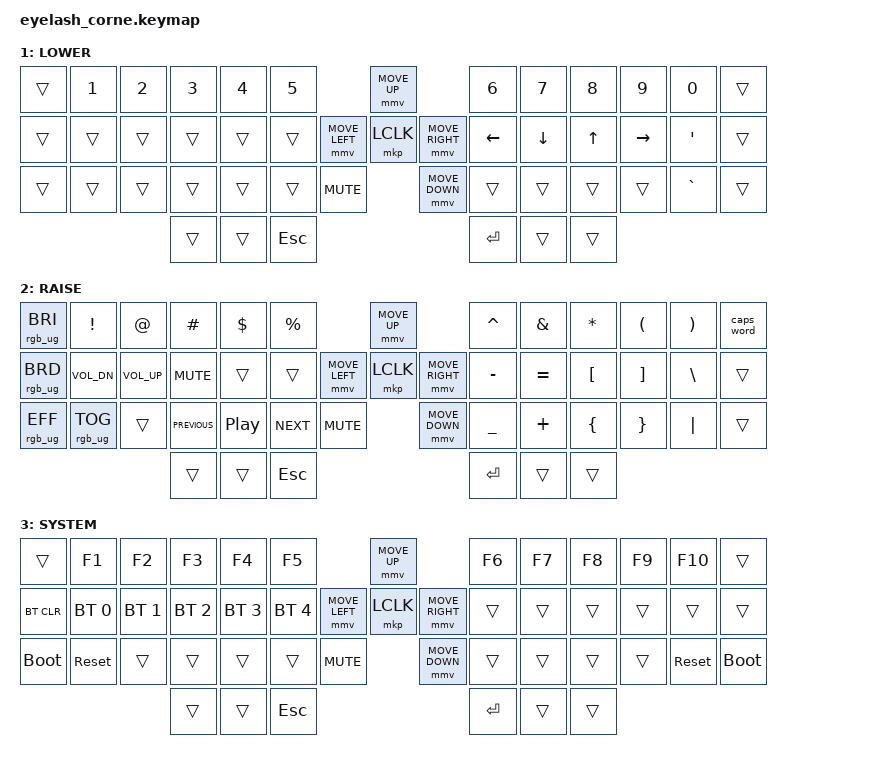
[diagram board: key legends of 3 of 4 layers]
#define ZMK_POINTING_DEFAULT_MOVE_VAL 1200  // 600
#define ZMK_POINTING_DEFAULT_SCRL_VAL 25   // 10

#include <input/processors.dtsi>
#include <zephyr/dt-bindings/input/input-event-codes.h>
#include <behaviors.dtsi>
#include <dt-bindings/zmk/bt.h>
#include <dt-bindings/zmk/keys.h>
#include <dt-bindings/zmk/outputs.h>
#include <dt-bindings/zmk/pointing.h>
#include <dt-bindings/zmk/rgb.h>

#define HRML(k1,k2,k3,k4) &ht LSHFT k1  &ht LALT k2  &ht LCTRL k3  &ht LGUI k4
#define HRMR(k1,k2,k3,k4) &ht RGUI k1  &ht RCTRL k2  &ht RALT k3  &ht RSHFT k4

&mmv_input_listener { input-processors = <&zip_xy_scaler 2 1>; };

&msc_input_listener { input-processors = <&zip_scroll_scaler 2 1>; };

&msc {
    acceleration-exponent = <1>;      // 0
    time-to-max-speed-ms = <100>;       // 300
    delay-ms = <0>;                   // 0
};

&mmv {
    time-to-max-speed-ms = <500>;
    acceleration-exponent = <1>;
    trigger-period-ms = <16>;
};

/ {
    behaviors {
         ht: hold_tap {
            compatible = "zmk,behavior-hold-tap";
            #binding-cells = <2>;
            flavor = "tap-preferred";
            tapping-term-ms = <220>;
            quick-tap-ms = <150>;
            require-prior-idle-ms = <100>;
            bindings = <&kp>, <&kp>;
        };
    };

    conditional_layers {
              compatible = "zmk,conditional-layers";
              tri_layer {
                if-layers = <1 2>;
                then-layer = <3>;
              };
    };
    rgb_encoder: rgb_encoder {
        compatible = "zmk,behavior-sensor-rotate";
        #sensor-binding-cells = <0>;
        bindings = <&rgb_ug RGB_BRI>, <&rgb_ug RGB_BRD>;
    };

    scroll_encoder: scroll_encoder {
        compatible = "zmk,behavior-sensor-rotate";
        #sensor-binding-cells = <0>;
        bindings = <&msc SCRL_DOWN>, <&msc SCRL_UP>;

        tap-ms = <100>;
    };

    keymap {
        compatible = "zmk,keymap";

// &kp TAB    &kp Q  &kp W  &kp E     &kp R  &kp T                               &kp UP                &kp Y        &kp U  &kp I      &kp O    &kp P     &kp BSPC
// &td0       &kp A  &kp S  &kp D     &kp F  &kp G                     &kp LEFT  &kp ENTER  &kp RIGHT  &kp H        &kp J  &kp K      &kp L    &kp SEMI  &kp SQT
// &kp LCTRL  &kp Z  &kp X  &kp C     &kp V  &kp B        &kp SPACE              &kp DOWN              &kp N        &kp M  &kp COMMA  &kp DOT  &kp FSLH  &kp ESC
//                          &kp LGUI  &mo 1  &lt 3 SPACE                                               &lt 3 ENTER  &mo 2  &kp RALT
// -----------------------------------------------------------------------------------------
// |      |  Q  |  W  |  E  |  R  |  T  |   |  Y  |  U   |  I  |  O  |  P  |      |
// |      |  A  |  S  |  D  |  F  |  G  |   |  H  |  J   |  K  |  L  |  ;  |      |
// |      |  Z  |  X  |  C  |  V  |  B  |   |  N  |  M   |  ,  |  .  |  /  |      |
//                    |     | LWR | SPC |   | ENT | RSE  |     |
        default_layer {
            display-name = "QWERTY";
            bindings = <
   &trans  &kp Q &kp W &kp E &kp R  &kp T                             &kp UP                   &kp Y &kp U  &kp I     &kp O   &kp P      &trans
   &trans HRML(A,  S,   D,    F) &kp G                      &kp LEFT  &kp ENTER  &kp RIGHT     &kp H HRMR(J,   K,    L,     SEMI)           &trans
   &trans   &kp Z &kp X &kp C &kp V &kp B     &kp SPACE               &kp DOWN                 &kp N &kp M  &kp COMMA &kp DOT &kp FSLH    &trans
                  &trans &lt 1 TAB &kp SPACE                                            &kp RET &lt 2 BSPC &trans
            >;
             sensor-bindings = <&inc_dec_kp C_VOLUME_UP C_VOLUME_DOWN>;

           
        };

        lower_layer {
            display-name = "LOWER";
// &trans  &kp N1           &kp N2          &kp N3        &kp N4        &kp N5                                         &mmv MOVE_UP                     &kp N6           &kp N7           &kp N8           &kp N9           &kp N0    &kp BSPC
// &trans  &bt BT_CLR_ALL   &bt BT_SEL 0    &bt BT_SEL 1  &bt BT_SEL 2  &bt BT_SEL 3                   &mmv MOVE_LEFT  &mkp LCLK       &mmv MOVE_RIGHT  &kp LEFT         &kp DOWN         &kp UP           &kp RIGHT        &kp HOME  &kp PG_UP
// &trans  &rgb_ug RGB_OFF  &rgb_ug RGB_ON  &trans        &trans        &rgb_ug RGB_EFF  &kp C_MUTE                    &mmv MOVE_DOWN                   &rgb_ug RGB_EFR  &rgb_ug RGB_SPI  &rgb_ug RGB_BRI  &rgb_ug RGB_BRD  &kp END   &kp PG_DN
//                                          &trans        &trans        &trans                                                                          &kp INS          &kp DEL          &trans
// -----------------------------------------------------------------------------------------
// |      |  1  |  2  |  3  |  4  |  5  |   |  6  |  7  |  8  |  9  |  0  |      |
// |      |     |     |     |     |     |   | LFT | DWN |  UP | RGT |  '  |      |
// |      |     |     |     |     |     |   |     |     |     |     |  `  |      |
//                    |     |     | ESC |   | ENT |     |     |
            bindings = <
   &trans  &kp N1       &kp N2       &kp N3       &kp N4       &kp N5                                                 &mmv MOVE_UP                                 &kp N6   &kp N7   &kp N8 &kp N9    &kp N0  &trans
   &trans  &trans       &trans       &trans       &trans       &trans                                 &mmv MOVE_LEFT  &mkp LCLK  &mmv MOVE_RIGHT                  &kp LEFT &kp DOWN &kp UP &kp RIGHT &kp SQT  &trans
   &trans  &trans       &trans       &trans       &trans       &trans         &kp C_MUTE                              &mmv MOVE_DOWN                              &trans   &trans   &trans &trans    &kp GRAVE &trans
                                     &trans       &trans       &kp ESC                                                                                            &kp RET  &trans   &trans
            >;

            sensor-bindings = <&scroll_encoder>;
        };

// &trans  &kp EXCL      &kp AT        &kp HASH   &kp DLLR   &kp PRCNT                            &mmv MOVE_UP                     &kp CARET  &kp AMPS   &kp ASTRK  &kp LPAR  &kp RPAR  &kp BSPC
// &trans  &bt BT_CLR    &mkp LCLK     &mkp MCLK  &mkp RCLK  &mkp MB4             &mmv MOVE_LEFT  &mkp LCLK       &mmv MOVE_RIGHT  &kp MINUS  &kp EQUAL  &kp LBKT   &kp RBKT  &kp BSLH  &kp GRAVE
// &trans  &out OUT_USB  &out OUT_BLE  &none      &none      &mkp MB5   &trans                    &mmv MOVE_DOWN                   &kp UNDER  &kp PLUS   &kp LBRC   &kp RBRC  &kp PIPE  &kp TILDE
//                                     &trans     &trans     &kp SPACE                                                             &kp RET    &trans     &trans

// -----------------------------------------------------------------------------------------
// |      |  !  |  @  |  #  |  $  |  %  |   |  ^  |  &  |  *  |  (  |  )  |      |
// |      |     |     |     |     |     |   |  -  |  =  |  [  |  ]  |  \  |      |
// |      |     |     |     |     |     |   |  _  |  +  |  {  |  }  | "|" |      |
//                    |     |     | ESC |   | ENT |     |     |
        raise_layer {
            display-name = "RAISE";
            bindings = <
   &rgb_ug RGB_BRI  &kp EXCL &kp AT &kp HASH &kp DLLR &kp PRCNT                                                           &mmv MOVE_UP                          &kp CARET &kp AMPS  &kp ASTRK &kp LPAR &kp RPAR &caps_word
   &rgb_ug RGB_BRD  &kp C_VOL_DN   &kp C_VOL_UP &kp C_MUTE   &trans   &trans                              &mmv MOVE_LEFT  &mkp LCLK  &mmv MOVE_RIGHT            &kp MINUS &kp EQUAL &kp LBKT  &kp RBKT &kp BSLH &trans
   &rgb_ug RGB_EFF  &rgb_ug RGB_TOG   &trans &kp C_PREVIOUS   &kp C_PP   &kp C_NEXT &kp C_MUTE                            &mmv MOVE_DOWN                        &kp UNDER &kp PLUS  &kp LBRC  &kp RBRC &kp PIPE &trans
                             &trans &trans   &kp ESC     &kp RET   &trans    &trans
            >;

            sensor-bindings = <&scroll_encoder>;
        };

  // -----------------------------------------------------------------------------------------
// |              | F1          |  F2 | F3  | F4  | F5  |   | F6  | F7  | F8  | F9  | F10         |            |
// | BTCLR        | BT1         | BT2 | BT3 | BT4 | BT5 |   | LFT | DWN |  UP | RGT |             |            |
// |  bootloader  |  sys_reset  |     |     |     |     |   |     |     |     |     |  sys_reset  | bootloader |
//                |             |     | ESC |               | ENT |     |     |
        layer_3 {
            display-name = "SYSTEM";
            bindings = <
   &trans       &kp F1          &kp F2          &kp F3          &kp F4          &kp F5                                            &mmv MOVE_UP                                            &kp F6      &kp F7      &kp F8    &kp F9      &kp F10      &trans
   &bt BT_CLR   &bt BT_SEL 0    &bt BT_SEL 1    &bt BT_SEL 2    &bt BT_SEL 3    &bt BT_SEL 4                      &mmv MOVE_LEFT &mkp LCLK  &mmv MOVE_RIGHT &trans      &trans      &trans    &trans      &trans      &trans
   &bootloader  &sys_reset      &trans          &trans          &trans          &trans &kp C_MUTE                               &mmv MOVE_DOWN            &trans      &trans      &trans    &trans      &sys_reset  &bootloader
                                &trans          &trans          &kp ESC                           &kp RET     &trans      &trans
            >;

            sensor-bindings = <&scroll_encoder>;
        };
    };
};
